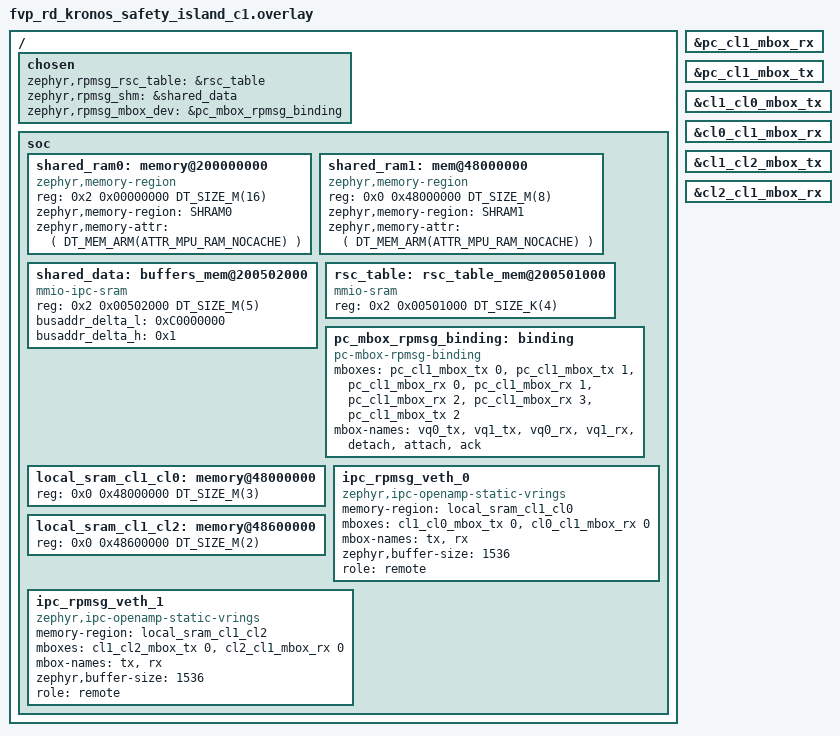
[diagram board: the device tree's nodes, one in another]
/*
 * SPDX-FileCopyrightText: <text>Copyright 2023-2024 Arm Limited and/or its
 * affiliates <open-source-office@arm.com></text>
 *
 * SPDX-License-Identifier: Apache-2.0
 */

/ {
	chosen {
		zephyr,rpmsg_rsc_table = &rsc_table;
		zephyr,rpmsg_shm = &shared_data;
		zephyr,rpmsg_mbox_dev = &pc_mbox_rpmsg_binding;
	};

	soc {
		shared_ram0: memory@200000000 {
			compatible = "zephyr,memory-region", "mmio-sram";
			reg = <0x2 0x00000000 DT_SIZE_M(16)>;
			zephyr,memory-region = "SHRAM0";
			zephyr,memory-attr = <( DT_MEM_ARM(ATTR_MPU_RAM_NOCACHE) )>;
		};

		shared_ram1: mem@48000000 {
			compatible = "zephyr,memory-region", "mmio-sram";
			reg = <0x0 0x48000000 DT_SIZE_M(8)>;
			zephyr,memory-region = "SHRAM1";
			zephyr,memory-attr = <( DT_MEM_ARM(ATTR_MPU_RAM_NOCACHE) )>;
		};

		shared_data: buffers_mem@200502000 {
			compatible = "mmio-ipc-sram";
			reg = <0x2 0x00502000 DT_SIZE_M(5)>;
			busaddr_delta_l = <0xC0000000>;
			busaddr_delta_h = <0x1>;
		};

		rsc_table: rsc_table_mem@200501000 {
			compatible = "mmio-sram";
			reg = <0x2 0x00501000 DT_SIZE_K(4)>;
		};

		pc_mbox_rpmsg_binding: binding {
			compatible = "pc-mbox-rpmsg-binding";
			mboxes = <&pc_cl1_mbox_tx 0>, <&pc_cl1_mbox_tx 1>,
				 <&pc_cl1_mbox_rx 0>, <&pc_cl1_mbox_rx 1>,
				 <&pc_cl1_mbox_rx 2>, <&pc_cl1_mbox_rx 3>,
				 <&pc_cl1_mbox_tx 2>;

			mbox-names = "vq0_tx", "vq1_tx", "vq0_rx",
				     "vq1_rx", "detach", "attach",
				     "ack";
		};

		local_sram_cl1_cl0: memory@48000000 {
			reg = <0x0 0x48000000 DT_SIZE_M(3)>;
		};

		ipc_rpmsg_veth_0: ipc_rpmsg_veth_0 {
			compatible = "zephyr,ipc-openamp-static-vrings";
			memory-region = <&local_sram_cl1_cl0>;
			mboxes = <&cl1_cl0_mbox_tx 0>, <&cl0_cl1_mbox_rx 0>;
			mbox-names = "tx", "rx";
			zephyr,buffer-size = <1536>;
			role = "remote";
			status = "okay";
		};

		local_sram_cl1_cl2: memory@48600000 {
			reg = <0x0 0x48600000 DT_SIZE_M(2)>;
		};

		ipc_rpmsg_veth_1: ipc_rpmsg_veth_1 {
			compatible = "zephyr,ipc-openamp-static-vrings";
			memory-region = <&local_sram_cl1_cl2>;
			mboxes = <&cl1_cl2_mbox_tx 0>, <&cl2_cl1_mbox_rx 0>;
			mbox-names = "tx", "rx";
			zephyr,buffer-size = <1536>;
			role = "remote";
			status = "okay";
		};
	};
};

&pc_cl1_mbox_rx {
	status = "okay";
};

&pc_cl1_mbox_tx {
	status = "okay";
};

&cl1_cl0_mbox_tx {
	status = "okay";
};

&cl0_cl1_mbox_rx {
	status = "okay";
};

&cl1_cl2_mbox_tx {
	status = "okay";
};

&cl2_cl1_mbox_rx {
	status = "okay";
};
